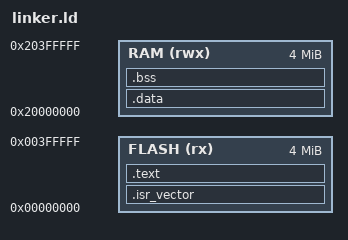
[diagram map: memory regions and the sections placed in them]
ENTRY(Reset_Handler)

MEMORY
{
    FLASH (rx)  : ORIGIN = 0x00000000, LENGTH = 4M
    RAM   (rwx) : ORIGIN = 0x20000000, LENGTH = 4M
}

_estack = ORIGIN(RAM) + LENGTH(RAM);

SECTIONS
{
    .isr_vector :
    {
        KEEP(*(.isr_vector))
    } > FLASH

    .text :
    {
        *(.text*)
        *(.rodata*)
        _sdata_flash = .;
    } > FLASH

    .data : AT(_sdata_flash)
    {
        _sdata = .;
        *(.data*)
        _edata = .;
    } > RAM

    .bss :
    {
        _sbss = .;
        *(.bss*)
        *(COMMON)
        _ebss = .;
    } > RAM
}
